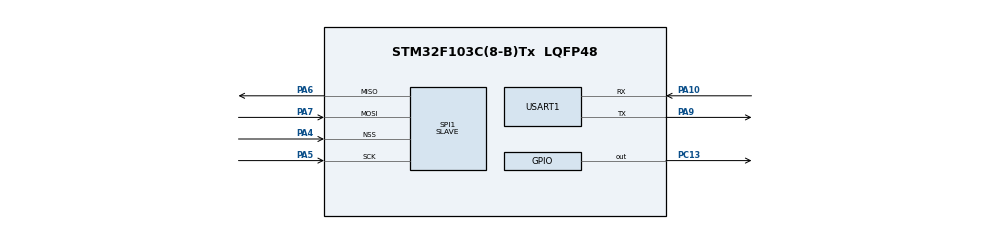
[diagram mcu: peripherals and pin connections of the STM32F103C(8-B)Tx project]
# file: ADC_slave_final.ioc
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Mcu.Family=STM32F1
Mcu.Name=STM32F103C(8-B)Tx
Mcu.Package=LQFP48
NVIC.PriorityGroup=NVIC_PRIORITYGROUP_4
NVIC.USART1_IRQn=true\:0\:0\:false\:false\:true\:true\:true\:true
PA10.Mode=Asynchronous
PA10.Signal=USART1_RX
PA13.Mode=Serial_Wire
PA13.Signal=SYS_JTMS-SWDIO
PA14.Mode=Serial_Wire
PA14.Signal=SYS_JTCK-SWCLK
PA4.Mode=NSS_Signal_Hard_Input
PA4.Signal=SPI1_NSS
PA5.Mode=Full_Duplex_Slave
PA5.Signal=SPI1_SCK
PA6.Mode=Full_Duplex_Slave
PA6.Signal=SPI1_MISO
PA7.Mode=Full_Duplex_Slave
PA7.Signal=SPI1_MOSI
PA9.Mode=Asynchronous
PA9.Signal=USART1_TX
PC13-TAMPER-RTC.Signal=GPIO_Output
ProjectManager.HeapSize=0x200
ProjectManager.StackSize=0x400
ProjectManager.TargetToolchain=MDK-ARM V5.32
RCC.APB1Freq_Value=8000000
RCC.APB2Freq_Value=8000000
SPI1.Direction=SPI_DIRECTION_2LINES
SPI1.Mode=SPI_MODE_SLAVE
SPI1.VirtualNSS=VM_NSSHARD
SPI1.VirtualType=VM_SLAVE
USART1.VirtualMode=VM_ASYNC
board=custom

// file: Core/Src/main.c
/* USER CODE BEGIN Header */
/**
  ******************************************************************************
  * @file           : main.c
  * @brief          : Main program body
  ******************************************************************************
  */
/* USER CODE END Header */
#include "main.h"
#include <stdio.h>
#include <string.h>
SPI_HandleTypeDef hspi1;
UART_HandleTypeDef huart1;

/* USER CODE BEGIN PV */
uint8_t spi_rx_buffer[2];
uint16_t received_adc_value = 0;
/* USER CODE END PV */

/* Function Prototypes */
void SystemClock_Config(void);
static void MX_GPIO_Init(void);
static void MX_SPI1_Init(void);
static void MX_USART1_UART_Init(void);

int main(void)
{
  HAL_Init();
  SystemClock_Config();

  MX_GPIO_Init();
  MX_SPI1_Init();
  MX_USART1_UART_Init();

  while (1)
  {
    if (HAL_SPI_Receive(&hspi1, spi_rx_buffer, 2, HAL_MAX_DELAY) == HAL_OK)
    {
      received_adc_value = (spi_rx_buffer[1] << 8) | spi_rx_buffer[0];

      char msg[30];
      int len = sprintf(msg, "ADC: %u\r\n", received_adc_value);
      HAL_UART_Transmit(&huart1, (uint8_t*)msg, len, HAL_MAX_DELAY);

      HAL_GPIO_TogglePin(GPIOC, GPIO_PIN_13);
      HAL_Delay(500); // Optional: to observe LED toggle
    }
  }
}

/* System Clock Configuration */
void SystemClock_Config(void)
{
  RCC_OscInitTypeDef RCC_OscInitStruct = {0};
  RCC_ClkInitTypeDef RCC_ClkInitStruct = {0};

  RCC_OscInitStruct.OscillatorType = RCC_OSCILLATORTYPE_HSI;
  RCC_OscInitStruct.HSIState = RCC_HSI_ON;
  RCC_OscInitStruct.PLL.PLLState = RCC_PLL_NONE;
  HAL_RCC_OscConfig(&RCC_OscInitStruct);

  RCC_ClkInitStruct.ClockType = RCC_CLOCKTYPE_HCLK | RCC_CLOCKTYPE_SYSCLK
                              | RCC_CLOCKTYPE_PCLK1 | RCC_CLOCKTYPE_PCLK2;
  RCC_ClkInitStruct.SYSCLKSource = RCC_SYSCLKSOURCE_HSI;
  RCC_ClkInitStruct.AHBCLKDivider = RCC_SYSCLK_DIV1;
  RCC_ClkInitStruct.APB1CLKDivider = RCC_HCLK_DIV1;
  RCC_ClkInitStruct.APB2CLKDivider = RCC_HCLK_DIV1;
  HAL_RCC_ClockConfig(&RCC_ClkInitStruct, FLASH_LATENCY_0);
}

/* SPI1 Init Function */
static void MX_SPI1_Init(void)
{
  hspi1.Instance = SPI1;
  hspi1.Init.Mode = SPI_MODE_SLAVE;
  hspi1.Init.Direction = SPI_DIRECTION_2LINES;
  hspi1.Init.DataSize = SPI_DATASIZE_8BIT;
  hspi1.Init.CLKPolarity = SPI_POLARITY_LOW;
  hspi1.Init.CLKPhase = SPI_PHASE_1EDGE;
  hspi1.Init.NSS = SPI_NSS_HARD_INPUT;
  hspi1.Init.FirstBit = SPI_FIRSTBIT_MSB;
  hspi1.Init.TIMode = SPI_TIMODE_DISABLE;
  hspi1.Init.CRCCalculation = SPI_CRCCALCULATION_DISABLE;
  hspi1.Init.CRCPolynomial = 10;
  HAL_SPI_Init(&hspi1);
}

/* USART1 Init Function */
static void MX_USART1_UART_Init(void)
{
  huart1.Instance = USART1;
  huart1.Init.BaudRate = 115200;
  huart1.Init.WordLength = UART_WORDLENGTH_8B;
  huart1.Init.StopBits = UART_STOPBITS_1;
  huart1.Init.Parity = UART_PARITY_NONE;
  huart1.Init.Mode = UART_MODE_TX_RX;
  huart1.Init.HwFlowCtl = UART_HWCONTROL_NONE;
  huart1.Init.OverSampling = UART_OVERSAMPLING_16;
  HAL_UART_Init(&huart1);
}

/* GPIO Init Function */
static void MX_GPIO_Init(void)
{
  GPIO_InitTypeDef GPIO_InitStruct = {0};

  __HAL_RCC_GPIOC_CLK_ENABLE();
  __HAL_RCC_GPIOA_CLK_ENABLE();

  HAL_GPIO_WritePin(GPIOC, GPIO_PIN_13, GPIO_PIN_RESET);

  GPIO_InitStruct.Pin = GPIO_PIN_13;
  GPIO_InitStruct.Mode = GPIO_MODE_OUTPUT_PP;
  GPIO_InitStruct.Pull = GPIO_NOPULL;
  GPIO_InitStruct.Speed = GPIO_SPEED_FREQ_LOW;
  HAL_GPIO_Init(GPIOC, &GPIO_InitStruct);
}

/* Error Handler */
void Error_Handler(void)
{
  __disable_irq();
  while (1) {}
}
